AUTOSAR XML (schema 4-2-2)
package /Components
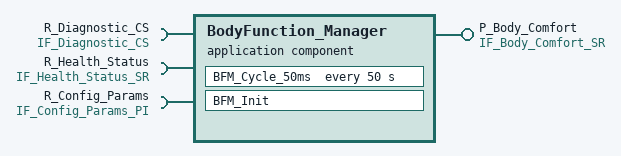
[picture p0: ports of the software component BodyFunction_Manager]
  application sw component type BodyFunction_Manager
    provide port P_Body_Comfort: provided-interface=IF_Body_Comfort_SR
    require port R_Diagnostic_CS: required-interface=IF_Diagnostic_CS
    require port R_Health_Status: required-interface=IF_Health_Status_SR
    require port R_Config_Params: required-interface=IF_Config_Params_PI
    behavior BodyFunction_Manager_InternalBehavior
      init event BFM_InitEvent: start-on-event=BFM_Init
      timing event BFM_Cyclic_50ms: start-on-event=BFM_Cycle_50ms, period=50
      runnable BFM_Init
        data-read-access:
          access Read_Temperature_Init: accessed-variable=R_Health_Status.temperature
          access Read_Voltage_Init: accessed-variable=R_Health_Status.voltage
        data-send-points:
          access Send_Default_HVAC_Setpoint_Init: accessed-variable=P_Body_Comfort.hvac_setpoint
          access Send_Default_Ambient_Light_Init: accessed-variable=P_Body_Comfort.ambient_light_level
        parameter access Access_Controller_Gains_Init: accessed-parameter=R_Config_Params.controller_gains
        parameter access Access_Limits_Init: accessed-parameter=R_Config_Params.limits
        parameter access Access_Security_Policy_Init: accessed-parameter=R_Config_Params.security_policy
      runnable BFM_Cycle_50ms: minimum-start-interval=50
        data-read-access:
          4 x access:
            Read_ECU_Health_Cycle: accessed-variable=R_Health_Status.ecu_health
            Read_Temperature_Cycle: accessed-variable=R_Health_Status.temperature
            Read_Voltage_Cycle: accessed-variable=R_Health_Status.voltage
            Read_Fault_Code_Cycle: accessed-variable=R_Health_Status.fault_code
        data-send-points:
          access Send_HVAC_Setpoint_Cycle: accessed-variable=P_Body_Comfort.hvac_setpoint
          access Send_Seat_Heater_Level_Cycle: accessed-variable=P_Body_Comfort.seat_heater_level
          access Send_Ambient_Light_Level_Cycle: accessed-variable=P_Body_Comfort.ambient_light_level
        parameter access Access_Limits_Cycle: accessed-parameter=R_Config_Params.limits
        parameter access Access_Controller_Gains_Cycle: accessed-parameter=R_Config_Params.controller_gains
